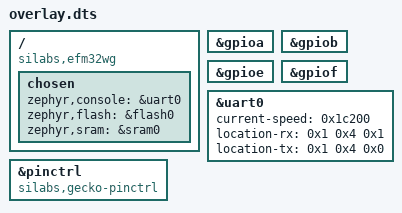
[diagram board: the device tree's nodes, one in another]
/ {
	compatible = "silabs,efm32wg", "silabs,efm32wg_stk3800";
	chosen {
		zephyr,console = &uart0;
		zephyr,flash = &flash0;
		zephyr,sram = &sram0;
	};
};
&gpioa{
	status = "okay";
};
&gpiob{
	status = "okay";
};
&gpioe{
	status = "okay";
};
&gpiof{
	status = "okay";
};
&uart0{
	status = "okay";
	current-speed = < 0x1c200 >;
	location-rx = < 0x1 0x4 0x1 >;
	location-tx = < 0x1 0x4 0x0 >;
};
&pinctrl{
	compatible = "silabs,gecko-pinctrl";
};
